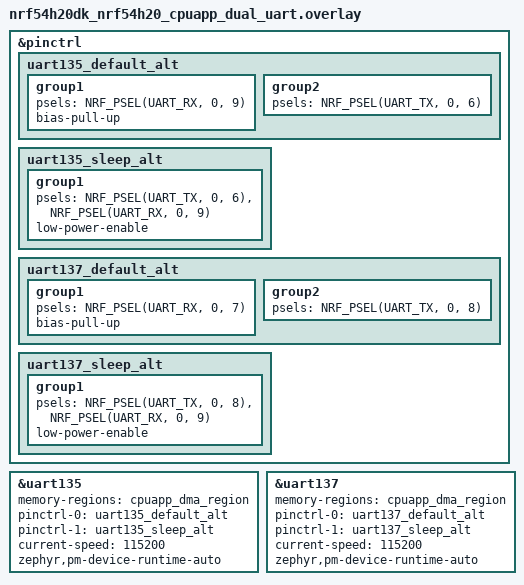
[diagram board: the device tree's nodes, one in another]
/* SPDX-License-Identifier: Apache-2.0 */

#include "nrf54h20dk_nrf54h20_common.dtsi"


&pinctrl {
	uart135_default_alt: uart135_default_alt {
		group1 {
			psels = <NRF_PSEL(UART_RX, 0, 9)>;
				bias-pull-up;
		};
		group2 {
			psels = <NRF_PSEL(UART_TX, 0, 6)>;
		};
	};

	uart135_sleep_alt: uart135_sleep_alt {
		group1 {
			psels = <NRF_PSEL(UART_TX, 0, 6)>,
				<NRF_PSEL(UART_RX, 0, 9)>;
			low-power-enable;
		};
	};
};

dut: &uart135 {
	status = "okay";
	memory-regions = <&cpuapp_dma_region>;
	pinctrl-0 = <&uart135_default_alt>;
	pinctrl-1 = <&uart135_sleep_alt>;
	pinctrl-names = "default", "sleep";
	current-speed = <115200>;
	zephyr,pm-device-runtime-auto;
};

&pinctrl {
	uart137_default_alt: uart137_default_alt {
		group1 {
			psels = <NRF_PSEL(UART_RX, 0, 7)>;
			bias-pull-up;
		};
		group2 {
			psels = <NRF_PSEL(UART_TX, 0, 8)>;
		};
	};

	uart137_sleep_alt: uart137_sleep_alt {
		group1 {
			psels = <NRF_PSEL(UART_TX, 0, 8)>,
				<NRF_PSEL(UART_RX, 0, 9)>;
			low-power-enable;
		};
	};
};

dut_aux: &uart137 {
	status = "okay";
	memory-regions = <&cpuapp_dma_region>;
	pinctrl-0 = <&uart137_default_alt>;
	pinctrl-1 = <&uart137_sleep_alt>;
	pinctrl-names = "default", "sleep";
	current-speed = <115200>;
	zephyr,pm-device-runtime-auto;
};
